# R7FA4L1BD register map
Vendor: Renesas Electronics Corporation; Series: RA4; File version: 0.90.02
CPU: CM33 r0p4, little endian, MPU, FPU, VTOR, 4 interrupt priority bits, 96 interrupts
Registers are 32-bit, read-write, reset 0x0 unless marked. A register's access mark holds for its fields unless they carry their own. Offsets are from the block's base; [hi:lo] are bit positions; {n}, {i} and the like mark numbered series; 'fields as' and 'values as' point back to an identical list.

## RTC — Realtime Clock
Base 0x40083000
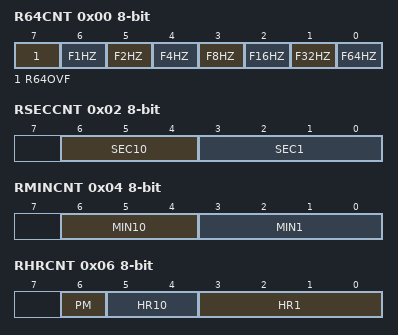
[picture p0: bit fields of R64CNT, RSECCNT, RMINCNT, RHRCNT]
0x00 R64CNT 8-bit ro reset not defined — 64-Hz Counter
  [7] R64OVF
  [6] F1HZ — 1-Hz Flag
  [5] F2HZ — 2-Hz Flag
  [4] F4HZ — 4-Hz Flag
  [3] F8HZ — 8-Hz Flag
  [2] F16HZ — 16-Hz Flag
  [1] F32HZ — 32-Hz Flag
  [0] F64HZ — 64-Hz Flag
{0x2+2i} BCNT{i} (i=0..3) 8-bit reset not defined — Binary Counter {i}
  [7:0] BCNT — Binary Counter
0x02 RSECCNT 8-bit reset not defined — Second Counter (in Calendar Count Mode)
  [6:4] SEC10 — 10-Second Count
  [3:0] SEC1 — 1-Second Count
0x04 RMINCNT 8-bit reset not defined — Minute Counter (in Calendar Count Mode)
  [6:4] MIN10 — 10-Minute Count
  [3:0] MIN1 — 1-Minute Count
0x06 RHRCNT 8-bit reset not defined — Hour Counter (in Calendar Count Mode)
  [6] PM — AM/PM select for time counter setting.
  [5:4] HR10 — 10-Hour Count
  [3:0] HR1 — 1-Hour Count
0x08 RWKCNT 8-bit reset not defined — Day,of,Week Counter (in Calendar Count Mode)
  [2:0] DAYW — Day,of,Week Counting
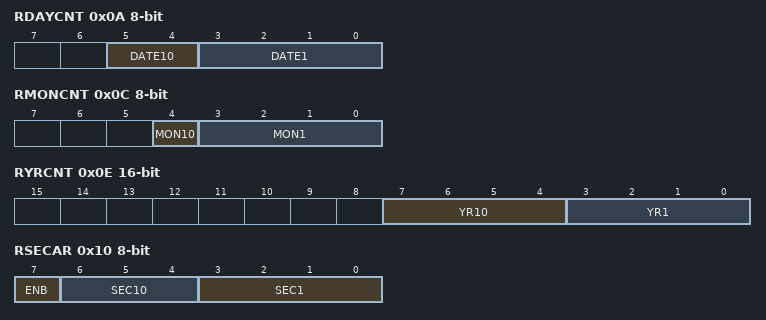
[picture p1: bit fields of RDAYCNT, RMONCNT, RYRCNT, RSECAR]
0x0A RDAYCNT 8-bit (reset mask 0xC0) — Day Counter
  [5:4] DATE10 — 10-Day Count
  [3:0] DATE1 — 1-Day Count
0x0C RMONCNT 8-bit (reset mask 0xE0) — Month Counter
  [4] MON10 — 10-Month Count
  [3:0] MON1 — 1-Month Count
0x0E RYRCNT 16-bit (reset mask 0xFF00) — Year Counter
  [7:4] YR10 — 10-Year Count
  [3:0] YR1 — 1-Year Count
{0x10+2i} BCNT{i}AR (i=0..3) 8-bit reset not defined — Binary Counter {i} Alarm Register
  [7:0] BCNTAR — Alarm register associated with the 32-bit binary counter
0x10 RSECAR 8-bit reset not defined — Second Alarm Register (in Calendar Count Mode)
  [7] ENB
  [6:4] SEC10 — 10 Seconds
  [3:0] SEC1 — 1 Second
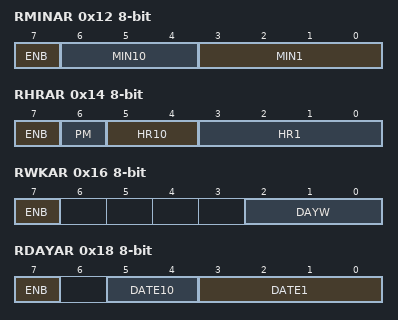
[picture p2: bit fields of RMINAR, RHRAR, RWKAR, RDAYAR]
0x12 RMINAR 8-bit reset not defined — Minute Alarm Register (in Calendar Count Mode)
  [7] ENB
  [6:4] MIN10 — 10 Minutes
  [3:0] MIN1 — 1 Minute
0x14 RHRAR 8-bit reset not defined — Hour Alarm Register (in Calendar Count Mode)
  [7] ENB
  [6] PM — AM/PM select for alarm setting.
  [5:4] HR10 — 10 Hours
  [3:0] HR1 — 1 Hour
0x16 RWKAR 8-bit reset not defined — Day,of,Week Alarm Register (in Calendar Count Mode)
  [7] ENB
  [2:0] DAYW — Day,of,Week Setting
{0x18+2i} BCNT{i}AER (i=0..1) 8-bit reset not defined — Binary Counter {i} Alarm Enable Register
  [7:0] ENB — Setting the alarm enable associated with the 32-bit binary counter
0x18 RDAYAR 8-bit reset not defined — Date Alarm Register (in Calendar Count Mode)
  [7] ENB
  [5:4] DATE10 — 10 Days
  [3:0] DATE1 — 1 Day
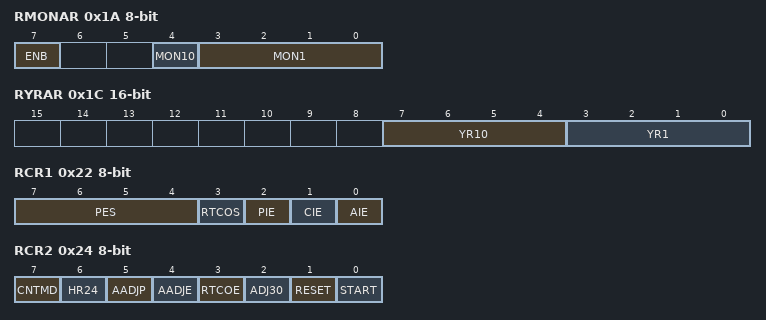
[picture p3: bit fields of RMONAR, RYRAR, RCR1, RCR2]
0x1A RMONAR 8-bit reset not defined — Month Alarm Register (in Calendar Count Mode)
  [7] ENB
  [4] MON10 — 10 Months
  [3:0] MON1 — 1 Month
0x1C BCNT2AER 16-bit (reset mask 0xFF00) — Binary Counter 2 Alarm Enable Register
  fields as BCNT0AER
0x1C RYRAR 16-bit (reset mask 0xFF00) (alternate view of BCNT2AER) — Year Alarm Register (in Calendar Count Mode)
  [7:4] YR10 — 10 Years
  [3:0] YR1 — 1 Year
0x1E BCNT3AER 8-bit reset not defined — Binary Counter 3 Alarm Enable Register
  fields as BCNT0AER
0x1E RYRAREN 8-bit reset not defined (alternate view of BCNT3AER) — Year Alarm Enable Register (in Calendar Count Mode)
  [7] ENB
0x22 RCR1 8-bit (reset mask 0xA) — RTC Control Register 1
  [7:4] PES — Periodic Interrupt Select
  [3] RTCOS — RTCOUT Output Select
  [2] PIE — Periodic Interrupt Enable
  [1] CIE — Carry Interrupt Enable
  [0] AIE — Alarm Interrupt Enable
0x24 RCR2 8-bit (reset mask 0xE) — RTC Control Register 2 (in Calendar Count Mode)
  [7] CNTMD — Count Mode Select
  [6] HR24 — Hours Mode
  [5] AADJP — Automatic Adjustment Period Select
  [4] AADJE — Automatic Adjustment Enable
  [3] RTCOE — RTCOUT Output Enable
  [2] ADJ30 — 30-Second Adjustment
  [1] RESET — RTC Software Reset
  [0] START
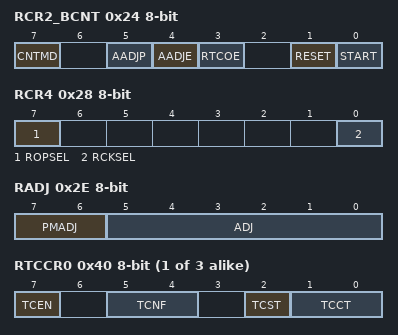
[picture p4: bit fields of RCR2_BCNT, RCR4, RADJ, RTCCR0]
0x24 RCR2_BCNT 8-bit (reset mask 0xE) (alternate view of RCR2) — RTC Control Register 2 (in Binary Count Mode)
  [7] CNTMD — Count Mode Select
  [5] AADJP — Automatic Adjustment Period Select
  [4] AADJE — Automatic Adjustment Enable
  [3] RTCOE — RTCOUT Output Enable
  [1] RESET — RTC Software Reset
  [0] START
0x28 RCR4 8-bit (reset mask 0x7E) — RTC Control Register 4
  [7] ROPSEL — RTC Operation Mode Select
  [0] RCKSEL — Count Source Select in normal operation mode
0x2A RFRH 16-bit (reset mask 0xFFFE) — Frequency Register H
  [0] RFC16 — Write 0 before writing to the RFRL register after a cold start.
0x2C RFRL 16-bit reset not defined — Frequency Register L
  [15:0] RFC — Frequency Comparison Value
0x2E RADJ 8-bit reset not defined — Time Error Adjustment Register
  [7:6] PMADJ — Plus,Minus
  [5:0] ADJ — Adjustment Value
{0x40+2i} RTCCR{i} (i=0..2) 8-bit (reset mask 0x48) — Time Capture Control Register {i}
  [7] TCEN — Time Capture Event Input Pin Enable
  [5:4] TCNF — Time Capture Noise Filter Control
  [2] TCST — Time Capture Status
  [1:0] TCCT — Time Capture Control
{0x52+0x10*i} BCNT0CP{i} (i=0..2) 8-bit ro reset not defined — BCNT0 Capture Register {i}
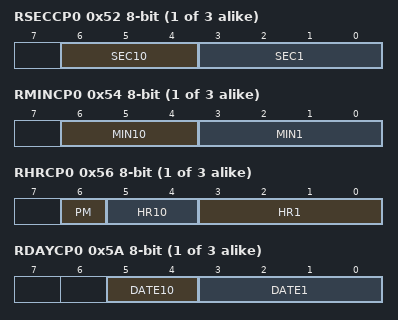
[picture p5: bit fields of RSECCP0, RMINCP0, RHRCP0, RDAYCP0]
{0x52+0x10*i} RSECCP{i} (i=0..2) 8-bit ro reset not defined (alternate view of BCNT0CP{i}) — Second Capture Register {i}
  [6:4] SEC10 — 10-Second Capture
  [3:0] SEC1 — 1-Second Capture
{0x54+0x10*i} BCNT1CP{i} (i=0..2) 8-bit ro reset not defined — BCNT1 Capture Register {i}
{0x54+0x10*i} RMINCP{i} (i=0..2) 8-bit ro reset not defined (alternate view of BCNT1CP{i}) — Minute Capture Register {i}
  [6:4] MIN10 — 10-Minute Capture
  [3:0] MIN1 — 1-Minute Capture
{0x56+0x10*i} BCNT2CP{i} (i=0..2) 8-bit ro reset not defined — BCNT2 Capture Register {i}
{0x56+0x10*i} RHRCP{i} (i=0..2) 8-bit ro reset not defined (alternate view of BCNT2CP{i}) — Hour Capture Register {i}
  [6] PM
  [5:4] HR10 — 10-Hour Capture
  [3:0] HR1 — 1-Hour Capture
{0x5A+0x10*i} BCNT3CP{i} (i=0..2) 8-bit ro reset not defined — BCNT3 Capture Register {i}
{0x5A+0x10*i} RDAYCP{i} (i=0..2) 8-bit ro reset not defined (alternate view of BCNT3CP{i}) — Date Capture Register {i}
  [5:4] DATE10 — 10-Day Capture
  [3:0] DATE1 — 1-Day Capture
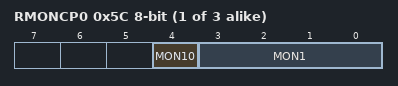
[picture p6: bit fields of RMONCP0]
{0x5C+0x10*i} RMONCP{i} (i=0..2) 8-bit ro (reset mask 0xE0) — Month Capture Register {i}
  [4] MON10 — 10-Month Capture
  [3:0] MON1 — 1-Month Capture
